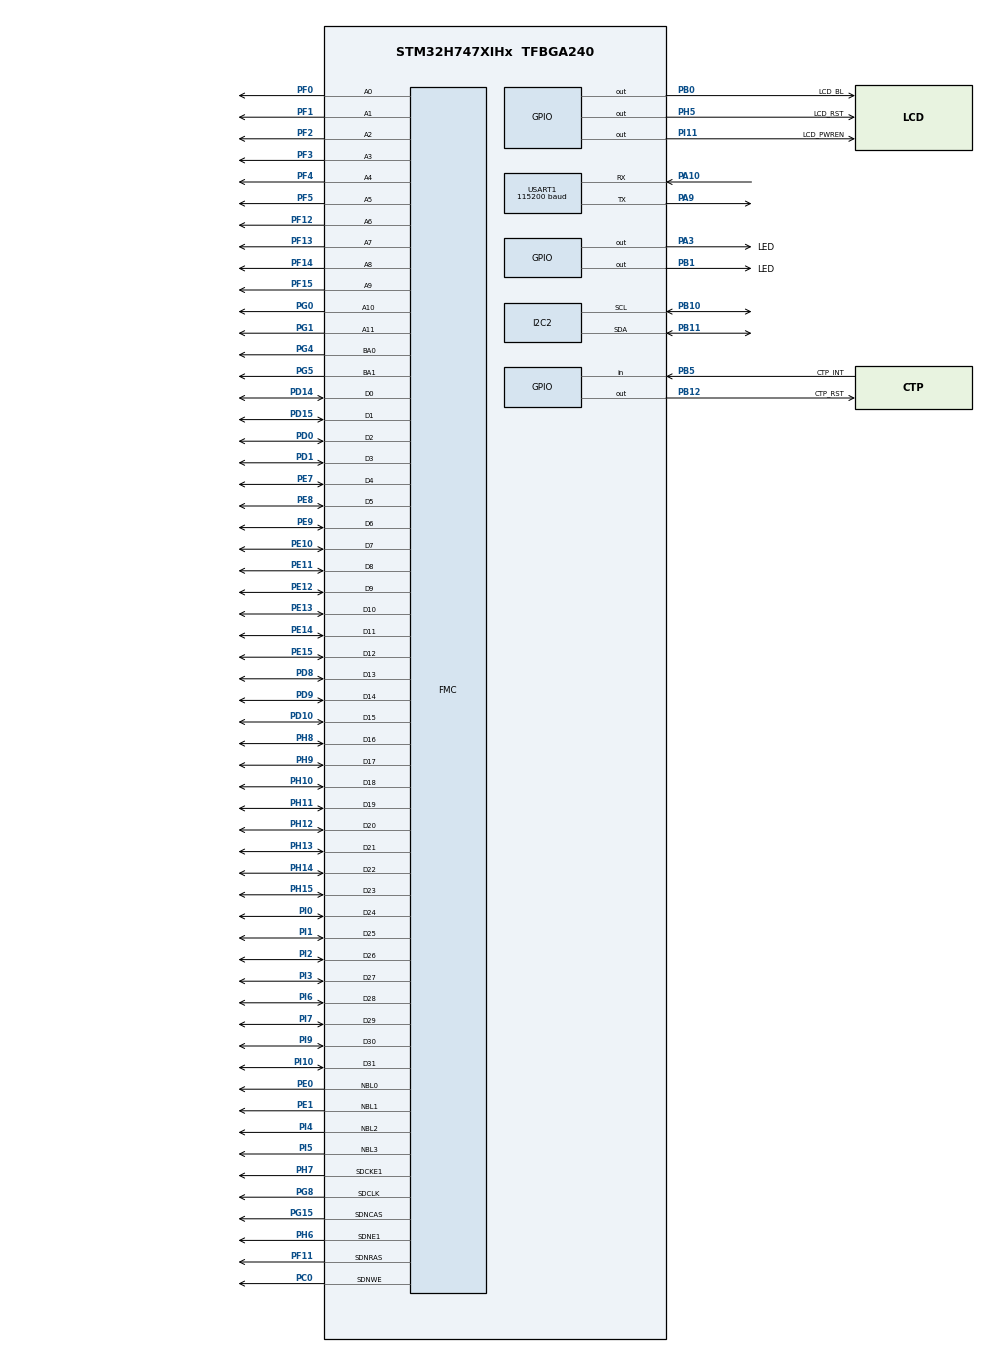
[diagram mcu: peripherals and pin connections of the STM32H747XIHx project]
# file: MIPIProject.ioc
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CORTEX_M7.AccessPermission_S-Cortex_Memory_Protection_Unit_Region1_Settings_S=MPU_REGION_FULL_ACCESS
CORTEX_M7.BaseAddress_S-Cortex_Memory_Protection_Unit_Region1_Settings_S=0xD0000000
CORTEX_M7.Enable_S-Cortex_Memory_Protection_Unit_Region1_Settings_S=MPU_REGION_ENABLE
CORTEX_M7.IsBufferable_S-Cortex_Memory_Protection_Unit_Region1_Settings_S=MPU_ACCESS_NOT_BUFFERABLE
CORTEX_M7.IsCacheable_S-Cortex_Memory_Protection_Unit_Region1_Settings_S=MPU_ACCESS_NOT_CACHEABLE
CORTEX_M7.IsShareable_S-Cortex_Memory_Protection_Unit_Region1_Settings_S=MPU_ACCESS_SHAREABLE
CORTEX_M7.Size_S-Cortex_Memory_Protection_Unit_Region1_Settings_S=MPU_REGION_SIZE_32MB
CORTEX_M7.default_mode_Activation=1
CortexM4.IPs=CORTEX_M4\:I,FATFS_M4\:I,FREERTOS_M4\:I,IWDG2\:I,OPENAMP_M4\:I,PDM2PCM_M4\:I,PWR,RCC,RESMGR_UTILITY,SYS_M4\:I,USB_DEVICE_M4\:I,USB_HOST_M4\:I,VREFBUF,WWDG2\:I,GPIO,DMA,BDMA,MDMA,NVIC2\:I
CortexM7.IPs=CORTEX_M7\:I,FATFS_M7\:I,FREERTOS_M7\:I,IWDG1\:I,OPENAMP_M7\:I,PDM2PCM_M7\:I,PWR\:I,RCC\:I,RESMGR_UTILITY\:I,SYS\:I,USB_DEVICE_M7\:I,USB_HOST_M7\:I,VREFBUF\:I,WWDG1\:I,GPIO\:I,DMA\:I,BDMA\:I,MDMA\:I,NVIC1\:I,FMC\:I,USART1\:I,DSIHOST\:I,LTDC\:I,DMA2D\:I,I2C2\:I
CortexM7.Pins=PB5,PI11,PH5,PB1,PB12,PA3,PB0
DMA2D.ColorMode=DMA2D_OUTPUT_RGB565
DMA2D.Mode=DMA2D_R2M
DSIHOST.BTA_FlowControl=__NULL
DSIHOST.ClockLaneHS2LPTime=35
DSIHOST.ClockLaneLP2HSTime=35
DSIHOST.DataLaneHS2LPTime=35
DSIHOST.DataLaneLP2HSTime=35
DSIHOST.HorizontalBackPorch=100
DSIHOST.HorizontalLine=1250
DSIHOST.HorizontalSyncActive=50
DSIHOST.LPCommandEnable=DSI_LP_COMMAND_ENABLE
DSIHOST.LPLargestPacketSize=4
DSIHOST.LPVACTLargestPacketSize=4
DSIHOST.Mode=DSI_VID_MODE_BURST
DSIHOST.NumberOfLanes=DSI_TWO_DATA_LANES
DSIHOST.StopWaitTime=10
DSI_CKN.Mode=DSIHost_Video
DSI_CKN.PinAttribute=CortexM7
DSI_CKN.Signal=DSIHOST_CKN
DSI_CKP.Mode=DSIHost_Video
DSI_CKP.PinAttribute=CortexM7
DSI_CKP.Signal=DSIHOST_CKP
DSI_D0N.Mode=DSIHost_Video
DSI_D0N.PinAttribute=CortexM7
DSI_D0N.Signal=DSIHOST_D0N
DSI_D0P.Mode=DSIHost_Video
DSI_D0P.PinAttribute=CortexM7
DSI_D0P.Signal=DSIHOST_D0P
DSI_D1N.Mode=DSIHost_Video
DSI_D1N.PinAttribute=CortexM7
DSI_D1N.Signal=DSIHOST_D1N
DSI_D1P.Mode=DSIHost_Video
DSI_D1P.PinAttribute=CortexM7
DSI_D1P.Signal=DSIHOST_D1P
Dma.Request0=USART1_RX
Dma.USART1_RX.0.Direction=DMA_PERIPH_TO_MEMORY
Dma.USART1_RX.0.EventEnable=DISABLE
Dma.USART1_RX.0.FIFOMode=DMA_FIFOMODE_DISABLE
Dma.USART1_RX.0.Instance=DMA1_Stream0
Dma.USART1_RX.0.MemDataAlignment=DMA_MDATAALIGN_BYTE
Dma.USART1_RX.0.MemInc=DMA_MINC_ENABLE
Dma.USART1_RX.0.Mode=DMA_NORMAL
Dma.USART1_RX.0.PeriphDataAlignment=DMA_PDATAALIGN_BYTE
Dma.USART1_RX.0.PeriphInc=DMA_PINC_DISABLE
Dma.USART1_RX.0.Polarity=HAL_DMAMUX_REQ_GEN_RISING
Dma.USART1_RX.0.Priority=DMA_PRIORITY_HIGH
Dma.USART1_RX.0.RequestNumber=1
Dma.USART1_RX.0.SignalID=NONE
Dma.USART1_RX.0.SyncEnable=DISABLE
Dma.USART1_RX.0.SyncPolarity=HAL_DMAMUX_SYNC_NO_EVENT
Dma.USART1_RX.0.SyncRequestNumber=1
Dma.USART1_RX.0.SyncSignalID=NONE
FMC.CASLatency2=FMC_SDRAM_CAS_LATENCY_2
FMC.ColumnBitsNumber2=FMC_SDRAM_COLUMN_BITS_NUM_9
FMC.ExitSelfRefreshDelay2=8
FMC.LoadToActiveDelay2=2
FMC.RCDDelay2=3
FMC.RPDelay1=3
FMC.RPDelay2=3
FMC.ReadBurst1=FMC_SDRAM_RBURST_ENABLE
FMC.ReadBurst2=FMC_SDRAM_RBURST_ENABLE
FMC.ReadPipeDelay1=FMC_SDRAM_RPIPE_DELAY_1
FMC.ReadPipeDelay2=FMC_SDRAM_RPIPE_DELAY_1
FMC.RowCycleDelay1=8
FMC.RowCycleDelay2=8
FMC.SDBank2=FMC_SDRAM_BANK2
FMC.SDClockPeriod1=FMC_SDRAM_CLOCK_PERIOD_2
FMC.SDClockPeriod2=FMC_SDRAM_CLOCK_PERIOD_2
FMC.SelfRefreshTime2=6
FMC.WriteRecoveryTime2=3
I2C2.Timing=0x307075B1
LTDC.ActiveH=1280
LTDC.ActiveW=800
LTDC.Alpha_L0=255
LTDC.FBStartAdress_L0=0xD0000000
LTDC.HBP=80
LTDC.HFP=80
LTDC.HSync=40
LTDC.ImageHeight_L0=1280
LTDC.ImageWidth_L0=800
LTDC.Layers=0
LTDC.PCPolarity=LTDC_PCPOLARITY_IPC
LTDC.PixelFormat_L0=LTDC_PIXEL_FORMAT_RGB565
LTDC.VBP=70
LTDC.VFP=70
LTDC.VSync=60
LTDC.WindowX1_L0=800
LTDC.WindowY1_L0=1280
Mcu.Family=STM32H7
Mcu.Name=STM32H747XIHx
Mcu.Package=TFBGA240
NVIC1.DMA1_Stream0_IRQn=true\:0\:0\:false\:false\:true\:false\:true\:true
NVIC1.PriorityGroup=NVIC_PRIORITYGROUP_4
NVIC1.USART1_IRQn=true\:0\:0\:false\:false\:true\:true\:true\:true
NVIC2.PriorityGroup=NVIC_PRIORITYGROUP_4
PA10.GPIO_Speed=GPIO_SPEED_FREQ_VERY_HIGH
PA10.Mode=Asynchronous
PA10.PinAttribute=CortexM7
PA10.Signal=USART1_RX
PA3.GPIO_Label=LED
PA3.GPIO_ModeDefaultOutputPP=GPIO_MODE_OUTPUT_PP
PA3.GPIO_PuPd=GPIO_PULLUP
PA3.GPIO_Speed=GPIO_SPEED_FREQ_VERY_HIGH
PA3.PinAttribute=CortexM7
PA3.PinState=GPIO_PIN_RESET
PA3.Signal=GPIO_Output
PA9.GPIO_Speed=GPIO_SPEED_FREQ_VERY_HIGH
PA9.Mode=Asynchronous
PA9.PinAttribute=CortexM7
PA9.Signal=USART1_TX
PB0.GPIO_Label=LCD_BL
PB0.GPIO_PuPd=GPIO_PULLUP
PB0.GPIO_Speed=GPIO_SPEED_FREQ_VERY_HIGH
PB0.PinAttribute=CortexM7
PB0.Signal=GPIO_Output
PB1.GPIO_Label=LED
PB1.GPIO_PuPd=GPIO_PULLUP
PB1.GPIO_Speed=GPIO_SPEED_FREQ_VERY_HIGH
PB1.PinAttribute=CortexM7
PB1.PinState=GPIO_PIN_SET
PB1.Signal=GPIO_Output
PB10.Mode=I2C
PB10.PinAttribute=CortexM7
PB10.Signal=I2C2_SCL
PB11.Mode=I2C
PB11.PinAttribute=CortexM7
PB11.Signal=I2C2_SDA
PB12.GPIO_Label=CTP_RST
PB12.GPIO_PuPd=GPIO_PULLUP
PB12.GPIO_Speed=GPIO_SPEED_FREQ_VERY_HIGH
PB12.PinAttribute=CortexM7
PB12.PinState=GPIO_PIN_SET
PB12.Signal=GPIO_Output
PB5.GPIO_Label=CTP_INT
PB5.GPIO_PuPd=GPIO_PULLUP
PB5.PinAttribute=CortexM7
PB5.Signal=GPIO_Input
PC0.GPIO_PuPd=GPIO_PULLUP
PC0.PinAttribute=CortexM7
PC0.Signal=FMC_SDNWE
PD0.GPIO_PuPd=GPIO_PULLUP
PD0.PinAttribute=CortexM7
PD0.Signal=FMC_D2_DA2
PD1.GPIO_PuPd=GPIO_PULLUP
PD1.PinAttribute=CortexM7
PD1.Signal=FMC_D3_DA3
PD10.GPIO_PuPd=GPIO_PULLUP
PD10.PinAttribute=CortexM7
PD10.Signal=FMC_D15_DA15
PD14.GPIO_PuPd=GPIO_PULLUP
PD14.PinAttribute=CortexM7
PD14.Signal=FMC_D0_DA0
PD15.GPIO_PuPd=GPIO_PULLUP
PD15.PinAttribute=CortexM7
PD15.Signal=FMC_D1_DA1
PD8.GPIO_PuPd=GPIO_PULLUP
PD8.PinAttribute=CortexM7
PD8.Signal=FMC_D13_DA13
PD9.GPIO_PuPd=GPIO_PULLUP
PD9.PinAttribute=CortexM7
PD9.Signal=FMC_D14_DA14
PE0.GPIO_PuPd=GPIO_PULLUP
PE0.PinAttribute=CortexM7
PE0.Signal=FMC_NBL0
PE1.GPIO_PuPd=GPIO_PULLUP
PE1.PinAttribute=CortexM7
PE1.Signal=FMC_NBL1
PE10.GPIO_PuPd=GPIO_PULLUP
PE10.PinAttribute=CortexM7
PE10.Signal=FMC_D7_DA7
PE11.GPIO_PuPd=GPIO_PULLUP
PE11.PinAttribute=CortexM7
PE11.Signal=FMC_D8_DA8
PE12.GPIO_PuPd=GPIO_PULLUP
PE12.PinAttribute=CortexM7
PE12.Signal=FMC_D9_DA9
PE13.GPIO_PuPd=GPIO_PULLUP
PE13.PinAttribute=CortexM7
PE13.Signal=FMC_D10_DA10
PE14.GPIO_PuPd=GPIO_PULLUP
PE14.PinAttribute=CortexM7
PE14.Signal=FMC_D11_DA11
PE15.GPIO_PuPd=GPIO_PULLUP
PE15.PinAttribute=CortexM7
PE15.Signal=FMC_D12_DA12
PE7.GPIO_PuPd=GPIO_PULLUP
PE7.PinAttribute=CortexM7
PE7.Signal=FMC_D4_DA4
PE8.GPIO_PuPd=GPIO_PULLUP
PE8.PinAttribute=CortexM7
PE8.Signal=FMC_D5_DA5
PE9.GPIO_PuPd=GPIO_PULLUP
PE9.PinAttribute=CortexM7
PE9.Signal=FMC_D6_DA6
PF0.GPIO_PuPd=GPIO_PULLUP
PF0.PinAttribute=CortexM7
PF0.Signal=FMC_A0
PF1.GPIO_PuPd=GPIO_PULLUP
PF1.PinAttribute=CortexM7
PF1.Signal=FMC_A1
PF11.GPIO_PuPd=GPIO_PULLUP
PF11.PinAttribute=CortexM7
PF11.Signal=FMC_SDNRAS
PF12.GPIO_PuPd=GPIO_PULLUP
PF12.PinAttribute=CortexM7
PF12.Signal=FMC_A6
PF13.GPIO_PuPd=GPIO_PULLUP
PF13.PinAttribute=CortexM7
PF13.Signal=FMC_A7
PF14.GPIO_PuPd=GPIO_PULLUP
PF14.PinAttribute=CortexM7
PF14.Signal=FMC_A8
PF15.GPIO_PuPd=GPIO_PULLUP
PF15.PinAttribute=CortexM7
PF15.Signal=FMC_A9
PF2.GPIO_PuPd=GPIO_PULLUP
PF2.PinAttribute=CortexM7
PF2.Signal=FMC_A2
PF3.GPIO_PuPd=GPIO_PULLUP
PF3.PinAttribute=CortexM7
PF3.Signal=FMC_A3
PF4.GPIO_PuPd=GPIO_PULLUP
PF4.PinAttribute=CortexM7
PF4.Signal=FMC_A4
PF5.GPIO_PuPd=GPIO_PULLUP
PF5.PinAttribute=CortexM7
PF5.Signal=FMC_A5
PG0.GPIO_PuPd=GPIO_PULLUP
PG0.PinAttribute=CortexM7
PG0.Signal=FMC_A10
PG1.GPIO_PuPd=GPIO_PULLUP
PG1.PinAttribute=CortexM7
PG1.Signal=FMC_A11
PG15.GPIO_PuPd=GPIO_PULLUP
PG15.PinAttribute=CortexM7
PG15.Signal=FMC_SDNCAS
PG4.GPIO_PuPd=GPIO_PULLUP
PG4.PinAttribute=CortexM7
PG4.Signal=FMC_A14_BA0
PG5.GPIO_PuPd=GPIO_PULLUP
PG5.PinAttribute=CortexM7
PG5.Signal=FMC_A15_BA1
PG8.GPIO_PuPd=GPIO_PULLUP
PG8.PinAttribute=CortexM7
PG8.Signal=FMC_SDCLK
PH0-OSC_IN\ (PH0).Mode=HSE-External-Oscillator
PH0-OSC_IN\ (PH0).PinAttribute=Free
PH0-OSC_IN\ (PH0).Signal=RCC_OSC_IN
PH1-OSC_OUT\ (PH1).Mode=HSE-External-Oscillator
PH1-OSC_OUT\ (PH1).PinAttribute=Free
PH1-OSC_OUT\ (PH1).Signal=RCC_OSC_OUT
PH10.GPIO_PuPd=GPIO_PULLUP
PH10.PinAttribute=CortexM7
PH10.Signal=FMC_D18
PH11.GPIO_PuPd=GPIO_PULLUP
PH11.PinAttribute=CortexM7
PH11.Signal=FMC_D19
PH12.GPIO_PuPd=GPIO_PULLUP
PH12.PinAttribute=CortexM7
PH12.Signal=FMC_D20
PH13.GPIO_PuPd=GPIO_PULLUP
PH13.PinAttribute=CortexM7
PH13.Signal=FMC_D21
PH14.GPIO_PuPd=GPIO_PULLUP
PH14.PinAttribute=CortexM7
PH14.Signal=FMC_D22
PH15.GPIO_PuPd=GPIO_PULLUP
PH15.PinAttribute=CortexM7
PH15.Signal=FMC_D23
PH5.GPIO_Label=LCD_RST
PH5.GPIO_PuPd=GPIO_PULLUP
PH5.GPIO_Speed=GPIO_SPEED_FREQ_VERY_HIGH
PH5.PinAttribute=CortexM7
PH5.PinState=GPIO_PIN_SET
PH5.Signal=GPIO_Output
PH6.GPIO_PuPd=GPIO_PULLUP
PH6.Mode=SdramChipSelect2_2
PH6.PinAttribute=CortexM7
PH6.Signal=FMC_SDNE1
PH7.GPIO_PuPd=GPIO_PULLUP
PH7.Mode=SdramChipSelect2_2
PH7.PinAttribute=CortexM7
PH7.Signal=FMC_SDCKE1
PH8.GPIO_PuPd=GPIO_PULLUP
PH8.PinAttribute=CortexM7
PH8.Signal=FMC_D16
PH9.GPIO_PuPd=GPIO_PULLUP
PH9.PinAttribute=CortexM7
PH9.Signal=FMC_D17
PI0.GPIO_PuPd=GPIO_PULLUP
PI0.PinAttribute=CortexM7
PI0.Signal=FMC_D24
PI1.GPIO_PuPd=GPIO_PULLUP
PI1.PinAttribute=CortexM7
PI1.Signal=FMC_D25
PI10.GPIO_PuPd=GPIO_PULLUP
PI10.PinAttribute=CortexM7
PI10.Signal=FMC_D31
PI11.GPIO_Label=LCD_PWREN
PI11.GPIO_PuPd=GPIO_PULLUP
PI11.GPIO_Speed=GPIO_SPEED_FREQ_VERY_HIGH
PI11.PinAttribute=CortexM7
PI11.Signal=GPIO_Output
PI2.GPIO_PuPd=GPIO_PULLUP
PI2.PinAttribute=CortexM7
PI2.Signal=FMC_D26
PI3.GPIO_PuPd=GPIO_PULLUP
PI3.PinAttribute=CortexM7
PI3.Signal=FMC_D27
PI4.GPIO_PuPd=GPIO_PULLUP
PI4.PinAttribute=CortexM7
PI4.Signal=FMC_NBL2
PI5.GPIO_PuPd=GPIO_PULLUP
PI5.PinAttribute=CortexM7
PI5.Signal=FMC_NBL3
PI6.GPIO_PuPd=GPIO_PULLUP
PI6.PinAttribute=CortexM7
PI6.Signal=FMC_D28
PI7.GPIO_PuPd=GPIO_PULLUP
PI7.PinAttribute=CortexM7
PI7.Signal=FMC_D29
PI9.GPIO_PuPd=GPIO_PULLUP
PI9.PinAttribute=CortexM7
PI9.Signal=FMC_D30
ProjectManager.HeapSize=M4-0x200,M7-0x200
ProjectManager.StackSize=M4-0x400,M7-0x400
ProjectManager.TargetToolchain=MDK-ARM V5.27
RCC.ADCFreq_Value=200000000
RCC.APB1Freq_Value=120000000
RCC.APB2Freq_Value=120000000
RCC.APB3Freq_Value=120000000
RCC.APB4Freq_Value=120000000
RCC.CortexFreq_Value=480000000
RCC.D1PPRE=RCC_APB3_DIV2
RCC.D2PPRE1=RCC_APB1_DIV2
RCC.D2PPRE2=RCC_APB2_DIV2
RCC.D3PPRE=RCC_APB4_DIV2
RCC.DIVM1=5
RCC.DIVM2=25
RCC.DIVM3=25
RCC.DIVN1=192
RCC.DIVN2=400
RCC.DIVN3=300
RCC.DIVQ2=8
RCC.DIVQ3=5
RCC.DIVR3=5
RCC.DSICLockSelection=RCC_DSICLKSOURCE_PHY
RCC.DSITX_Div=10
RCC.FMCCLockSelection=RCC_FMCCLKSOURCE_PLL2
RCC.HCLKFreq_Value=240000000
RCC.HPRE=RCC_HCLK_DIV2
RCC.HSE_VALUE=25000000
RCC.PLL2FRACN=0
RCC.PLL3FRACN=0
RCC.PLLDSIIDF=DSI_PLL_IN_DIV5
RCC.PLLDSINDIV=120
RCC.PLLFRACN=0
RCC.PLLSourceVirtual=RCC_PLLSOURCE_HSE
RCC.SYSCLKFreq_VALUE=480000000
RCC.SYSCLKSource=RCC_SYSCLKSOURCE_PLLCLK
RCC.USBFreq_Value=480000000
SH.FMC_A0.0=FMC_A0,12b-sda2
SH.FMC_A1.0=FMC_A1,12b-sda2
SH.FMC_A10.0=FMC_A10,12b-sda2
SH.FMC_A11.0=FMC_A11,12b-sda2
SH.FMC_A14_BA0.0=FMC_BA0,FourSdramBanks2
SH.FMC_A15_BA1.0=FMC_BA1,FourSdramBanks2
SH.FMC_A2.0=FMC_A2,12b-sda2
SH.FMC_A3.0=FMC_A3,12b-sda2
SH.FMC_A4.0=FMC_A4,12b-sda2
SH.FMC_A5.0=FMC_A5,12b-sda2
SH.FMC_A6.0=FMC_A6,12b-sda2
SH.FMC_A7.0=FMC_A7,12b-sda2
SH.FMC_A8.0=FMC_A8,12b-sda2
SH.FMC_A9.0=FMC_A9,12b-sda2
SH.FMC_D0_DA0.0=FMC_D0,sd-32b-d2
SH.FMC_D10_DA10.0=FMC_D10,sd-32b-d2
SH.FMC_D11_DA11.0=FMC_D11,sd-32b-d2
SH.FMC_D12_DA12.0=FMC_D12,sd-32b-d2
SH.FMC_D13_DA13.0=FMC_D13,sd-32b-d2
SH.FMC_D14_DA14.0=FMC_D14,sd-32b-d2
SH.FMC_D15_DA15.0=FMC_D15,sd-32b-d2
SH.FMC_D16.0=FMC_D16,sd-32b-d2
SH.FMC_D17.0=FMC_D17,sd-32b-d2
SH.FMC_D18.0=FMC_D18,sd-32b-d2
SH.FMC_D19.0=FMC_D19,sd-32b-d2
SH.FMC_D1_DA1.0=FMC_D1,sd-32b-d2
SH.FMC_D20.0=FMC_D20,sd-32b-d2
SH.FMC_D21.0=FMC_D21,sd-32b-d2
SH.FMC_D22.0=FMC_D22,sd-32b-d2
SH.FMC_D23.0=FMC_D23,sd-32b-d2
SH.FMC_D24.0=FMC_D24,sd-32b-d2
SH.FMC_D25.0=FMC_D25,sd-32b-d2
SH.FMC_D26.0=FMC_D26,sd-32b-d2
SH.FMC_D27.0=FMC_D27,sd-32b-d2
SH.FMC_D28.0=FMC_D28,sd-32b-d2
SH.FMC_D29.0=FMC_D29,sd-32b-d2
SH.FMC_D2_DA2.0=FMC_D2,sd-32b-d2
SH.FMC_D30.0=FMC_D30,sd-32b-d2
SH.FMC_D31.0=FMC_D31,sd-32b-d2
SH.FMC_D3_DA3.0=FMC_D3,sd-32b-d2
SH.FMC_D4_DA4.0=FMC_D4,sd-32b-d2
SH.FMC_D5_DA5.0=FMC_D5,sd-32b-d2
SH.FMC_D6_DA6.0=FMC_D6,sd-32b-d2
SH.FMC_D7_DA7.0=FMC_D7,sd-32b-d2
SH.FMC_D8_DA8.0=FMC_D8,sd-32b-d2
SH.FMC_D9_DA9.0=FMC_D9,sd-32b-d2
SH.FMC_NBL0.0=FMC_NBL0,Sd4ByteEnable2
SH.FMC_NBL1.0=FMC_NBL1,Sd4ByteEnable2
SH.FMC_NBL2.0=FMC_NBL2,Sd4ByteEnable2
SH.FMC_NBL3.0=FMC_NBL3,Sd4ByteEnable2
SH.FMC_SDCLK.0=FMC_SDCLK,12b-sda2
SH.FMC_SDNCAS.0=FMC_SDNCAS,12b-sda2
SH.FMC_SDNRAS.0=FMC_SDNRAS,12b-sda2
SH.FMC_SDNWE.0=FMC_SDNWE,12b-sda2
SYS.userName=SYS_M7
USART1.BaudRate=115200
USART1.Parity=PARITY_NONE
USART1.VirtualMode-Asynchronous=VM_ASYNC
VP_DMA2D_VS_DMA2D.Mode=DMA2D_Activate
VP_LTDC_DSIMode.Mode=RGB565
VP_SYS_M4_VS_Systick.Mode=SysTick
board=custom

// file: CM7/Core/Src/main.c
/* USER CODE BEGIN Header */
/**
  ******************************************************************************
  * @file           : main.c
  * @brief          : Main program body
  ******************************************************************************
  * @attention
  *
  * Copyright (c) 2026 STMicroelectronics.
  * All rights reserved.
  *
  * This software is licensed under terms that can be found in the LICENSE file
  * in the root directory of this software component.
  * If no LICENSE file comes with this software, it is provided AS-IS.
  *
  ******************************************************************************
  */
/* USER CODE END Header */
#include "main.h"
#include "dma.h"
#include "i2c.h"
#include "usart.h"
#include "gpio.h"
#include "fmc.h"

/* USER CODE BEGIN Includes */
#include "bsp_system.h"

/* USER CODE END Includes */

/* USER CODE BEGIN PD */

#ifndef HSEM_ID_0
#define HSEM_ID_0 (0U) /* HW semaphore 0*/
#endif

/* USER CODE END PD */

void SystemClock_Config(void);
static void MPU_Config(void);

/* USER CODE BEGIN 0 */
extern void lv_port_disp_init(void);
extern void lv_port_indev_init(void);

lv_ui guider_ui;
/* USER CODE END 0 */

int main(void)
{

/* USER CODE BEGIN Boot_Mode_Sequence_0 */
  int32_t timeout;
/* USER CODE END Boot_Mode_Sequence_0 */

  /* MPU Configuration--------------------------------------------------------*/
  MPU_Config();

/* USER CODE BEGIN Boot_Mode_Sequence_1 */
  /* Wait until CPU2 boots and enters in stop mode or timeout*/
  timeout = 0xFFFF;
  while((__HAL_RCC_GET_FLAG(RCC_FLAG_D2CKRDY) != RESET) && (timeout-- > 0));
  if ( timeout < 0 )
  {
  Error_Handler();
  }
/* USER CODE END Boot_Mode_Sequence_1 */
  /* MCU Configuration--------------------------------------------------------*/

  /* Reset of all peripherals, Initializes the Flash interface and the Systick. */
  HAL_Init();

  /* Configure the system clock */
  SystemClock_Config();
/* USER CODE BEGIN Boot_Mode_Sequence_2 */
/* When system initialization is finished, Cortex-M7 will release Cortex-M4 by means of
HSEM notification */
/*HW semaphore Clock enable*/
__HAL_RCC_HSEM_CLK_ENABLE();
/*Take HSEM */
HAL_HSEM_FastTake(HSEM_ID_0);
/*Release HSEM in order to notify the CPU2(CM4)*/
HAL_HSEM_Release(HSEM_ID_0,0);
/* wait until CPU2 wakes up from stop mode */
timeout = 0xFFFF;
while((__HAL_RCC_GET_FLAG(RCC_FLAG_D2CKRDY) == RESET) && (timeout-- > 0));
if ( timeout < 0 )
{
Error_Handler();
}
/* USER CODE END Boot_Mode_Sequence_2 */

  /* USER CODE BEGIN SysInit */
//	__HAL_RCC_CSI_ENABLE();
//	__HAL_RCC_SYSCFG_CLK_ENABLE();
//	HAL_EnableCompensationCell();
  /* USER CODE END SysInit */

  /* Initialize all configured peripherals */
  MX_GPIO_Init();
  MX_DMA_Init();
  MX_FMC_Init();
  MX_USART1_UART_Init();
  MX_I2C2_Init();
  /* USER CODE BEGIN 2 */
	green_led(2);
	purple_led(2);
	if (sdram_init(&hsdram2) != 0U)
	{
		printf("SDRAM init failed\r\n");
		Error_Handler();
	}
	printf("SDRAM init success\r\n");

	/* 先准备完整帧缓冲，再启动 LTDC/DSI，保持已验证的启动顺序。 */
//	SCB_CleanDCache_by_Addr(
//		(uint32_t *)LCD_FRAMEBUFFER,
//		LCD_WIDTH * LCD_HEIGHT * LCD_PIXEL_BYTES
//	);

	MX_DSIHOST_DSI_Init();
	MX_LTDC_Init();
	MX_DMA2D_Init();
	printf("DSI/LTDC/DMA2D init done\r\n");

	if (MIPI_LCD_Init() != HAL_OK)
	{
		printf("LCD init failed\r\n");
		Error_Handler();
	}
	if (Touch_Init() != HAL_OK)
	{
		printf("Touch init failed\r\n");
		Error_Handler();
	}
	printf("Touch init success\r\n");

	lv_init();
	lv_tick_set_cb(HAL_GetTick);
	lv_port_disp_init();
	lv_port_indev_init();
	setup_ui(&guider_ui);
	custom_init(&guider_ui);

	xTaskCreate(lvgl_task, "lvgl", 1024, NULL, tskIDLE_PRIORITY + 2, NULL);
	xTaskCreate(freertos_test_task, "test", 256, NULL, tskIDLE_PRIORITY + 1, NULL);
    vTaskStartScheduler();

  /* USER CODE END 2 */

  /* Infinite loop */
  while (1)
  {

  }
}

void SystemClock_Config(void)
{
  RCC_OscInitTypeDef RCC_OscInitStruct = {0};
  RCC_ClkInitTypeDef RCC_ClkInitStruct = {0};

  /** Supply configuration update enable
  */
  HAL_PWREx_ConfigSupply(PWR_LDO_SUPPLY);

  /** Configure the main internal regulator output voltage
  */
  __HAL_PWR_VOLTAGESCALING_CONFIG(PWR_REGULATOR_VOLTAGE_SCALE0);

  while(!__HAL_PWR_GET_FLAG(PWR_FLAG_VOSRDY)) {}

  /** Initializes the RCC Oscillators according to the specified parameters
  * in the RCC_OscInitTypeDef structure.
  */
  RCC_OscInitStruct.OscillatorType = RCC_OSCILLATORTYPE_HSE;
  RCC_OscInitStruct.HSEState = RCC_HSE_ON;
  RCC_OscInitStruct.PLL.PLLState = RCC_PLL_ON;
  RCC_OscInitStruct.PLL.PLLSource = RCC_PLLSOURCE_HSE;
  RCC_OscInitStruct.PLL.PLLM = 5;
  RCC_OscInitStruct.PLL.PLLN = 192;
  RCC_OscInitStruct.PLL.PLLP = 2;
  RCC_OscInitStruct.PLL.PLLQ = 2;
  RCC_OscInitStruct.PLL.PLLR = 2;
  RCC_OscInitStruct.PLL.PLLRGE = RCC_PLL1VCIRANGE_2;
  RCC_OscInitStruct.PLL.PLLVCOSEL = RCC_PLL1VCOWIDE;
  RCC_OscInitStruct.PLL.PLLFRACN = 0;
  if (HAL_RCC_OscConfig(&RCC_OscInitStruct) != HAL_OK)
  {
    Error_Handler();
  }

  /** Initializes the CPU, AHB and APB buses clocks
  */
  RCC_ClkInitStruct.ClockType = RCC_CLOCKTYPE_HCLK|RCC_CLOCKTYPE_SYSCLK
                              |RCC_CLOCKTYPE_PCLK1|RCC_CLOCKTYPE_PCLK2
                              |RCC_CLOCKTYPE_D3PCLK1|RCC_CLOCKTYPE_D1PCLK1;
  RCC_ClkInitStruct.SYSCLKSource = RCC_SYSCLKSOURCE_PLLCLK;
  RCC_ClkInitStruct.SYSCLKDivider = RCC_SYSCLK_DIV1;
  RCC_ClkInitStruct.AHBCLKDivider = RCC_HCLK_DIV2;
  RCC_ClkInitStruct.APB3CLKDivider = RCC_APB3_DIV2;
  RCC_ClkInitStruct.APB1CLKDivider = RCC_APB1_DIV2;
  RCC_ClkInitStruct.APB2CLKDivider = RCC_APB2_DIV2;
  RCC_ClkInitStruct.APB4CLKDivider = RCC_APB4_DIV2;

  if (HAL_RCC_ClockConfig(&RCC_ClkInitStruct, FLASH_LATENCY_4) != HAL_OK)
  {
    Error_Handler();
  }
}

 /* MPU Configuration */

void MPU_Config(void)
{
  MPU_Region_InitTypeDef MPU_InitStruct = {0};

  /* Disables the MPU */
  HAL_MPU_Disable();

  /** Initializes and configures the Region and the memory to be protected
  */
  MPU_InitStruct.Enable = MPU_REGION_ENABLE;
  MPU_InitStruct.Number = MPU_REGION_NUMBER0;
  MPU_InitStruct.BaseAddress = 0x0;
  MPU_InitStruct.Size = MPU_REGION_SIZE_4GB;
  MPU_InitStruct.SubRegionDisable = 0x87;
  MPU_InitStruct.TypeExtField = MPU_TEX_LEVEL0;
  MPU_InitStruct.AccessPermission = MPU_REGION_NO_ACCESS;
  MPU_InitStruct.DisableExec = MPU_INSTRUCTION_ACCESS_DISABLE;
  MPU_InitStruct.IsShareable = MPU_ACCESS_SHAREABLE;
  MPU_InitStruct.IsCacheable = MPU_ACCESS_NOT_CACHEABLE;
  MPU_InitStruct.IsBufferable = MPU_ACCESS_NOT_BUFFERABLE;

  HAL_MPU_ConfigRegion(&MPU_InitStruct);

  /** Initializes and configures the Region and the memory to be protected
  */
  MPU_InitStruct.Number = MPU_REGION_NUMBER1;
  MPU_InitStruct.BaseAddress = 0xD0000000;
  MPU_InitStruct.Size = MPU_REGION_SIZE_32MB;
  MPU_InitStruct.SubRegionDisable = 0x0;
  MPU_InitStruct.AccessPermission = MPU_REGION_FULL_ACCESS;
  MPU_InitStruct.DisableExec = MPU_INSTRUCTION_ACCESS_ENABLE;

  HAL_MPU_ConfigRegion(&MPU_InitStruct);
  /* Enables the MPU */
  HAL_MPU_Enable(MPU_PRIVILEGED_DEFAULT);

}

void Error_Handler(void)
{
  __disable_irq();
  while (1)
  {
  }
}
